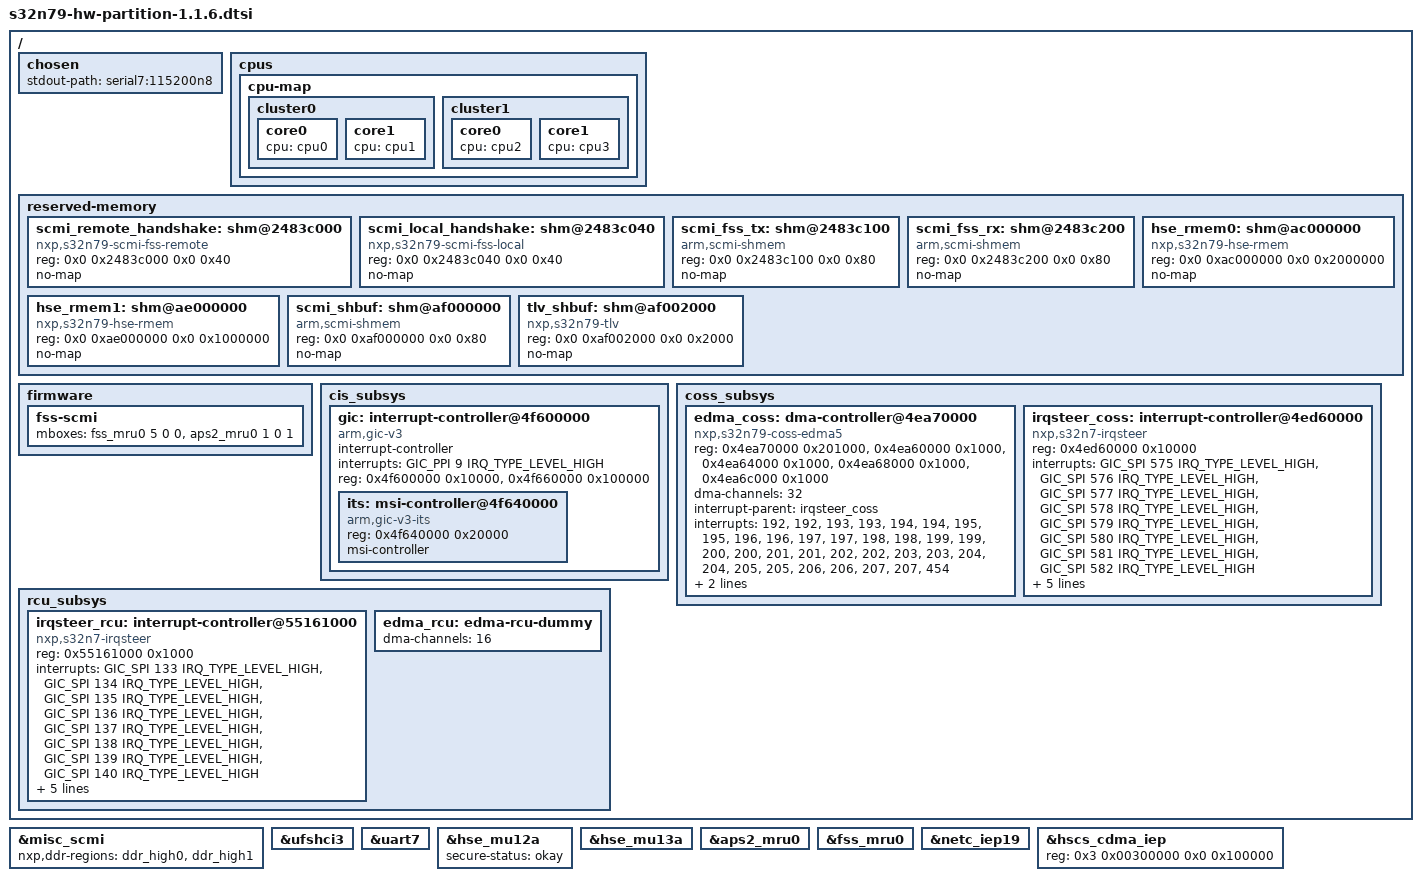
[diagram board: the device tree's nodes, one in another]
// SPDX-License-Identifier: (GPL-2.0+ OR BSD-3-Clause)
/*
 * Copyright 2025-2026 NXP
 */

#include "s32n79-hw-partition-1.1.6-ddr.dtsi"

/delete-node/ &gic;
/delete-node/ &cpu4;
/delete-node/ &cpu5;
/delete-node/ &cpu6;
/delete-node/ &cpu7;
/delete-node/ &irqsteer_coss;
/delete-node/ &irqsteer_rcu;
/delete-node/ &edma_coss;
/delete-node/ &edma_rcu;
/delete-node/ &netc_iep14;
/delete-node/ &netc_iep18;
/delete-node/ &sec_jr0;
/delete-node/ &sec_jr1;
/delete-node/ &sec_jr2;
/delete-node/ &sec_jr3;
/delete-node/ &sec_jr4;
/delete-node/ &sec_jr5;
/delete-node/ &sec_jr6;
/delete-node/ &sec_jr7;
/delete-node/ &sec_jr8;
/delete-node/ &sec_jr9;
/delete-node/ &sec_jr10;
/delete-node/ &sec_jr11;
/delete-node/ &ufshc;
/delete-node/ &ufshci0;
/delete-node/ &ufshci1;
/delete-node/ &ufshci2;

/ {
	chosen {
		stdout-path = "serial7:115200n8";
	};

	cpus {
		cpu-map {
			cluster0 {
				core0 {
					cpu = <&cpu0>;
				};

				core1 {
					cpu = <&cpu1>;
				};
			};

			cluster1 {
				core0 {
					cpu = <&cpu2>;
				};

				core1 {
					cpu = <&cpu3>;
				};
			};
		};
	};

	reserved-memory {
		#address-cells = <2>;
		#size-cells = <2>;
		ranges;

		scmi_remote_handshake: shm@2483c000 {
			compatible = "nxp,s32n79-scmi-fss-remote";
			reg = <0x0 0x2483c000 0x0 0x40>;
			no-map;
		};

		scmi_local_handshake: shm@2483c040 {
			compatible = "nxp,s32n79-scmi-fss-local";
			reg = <0x0 0x2483c040 0x0 0x40>;
			no-map;
		};
		/* FSS SCMI TX Mailbox */
		scmi_fss_tx: shm@2483c100 {
			compatible = "arm,scmi-shmem";
			reg = <0x0 0x2483c100 0x0 0x80>;
			no-map;
		};

		/* FSS SCMI RX Mailbox */
		scmi_fss_rx: shm@2483c200 {
			compatible = "arm,scmi-shmem";
			reg = <0x0 0x2483c200 0x0 0x80>;
			no-map;
		};

		hse_rmem0: shm@ac000000 {
			compatible = "nxp,s32n79-hse-rmem";
			reg = <0x0 0xac000000 0x0 0x2000000>; /* 32 MB */
			no-map;
		};

		hse_rmem1: shm@ae000000 {
			compatible = "nxp,s32n79-hse-rmem";
			reg = <0x0 0xae000000 0x0 0x1000000>; /* 16 MB */
			no-map;
		};

		scmi_shbuf: shm@af000000 {
			compatible = "arm,scmi-shmem";
			reg = <0x0 0xaf000000 0x0 0x80>;
			no-map;
		};

		tlv_shbuf: shm@af002000 {
			compatible = "nxp,s32n79-tlv";
			reg = <0x0 0xaf002000 0x0 0x2000>;
			no-map;
		};
	};

	firmware {
		fss-scmi {
			/*
			 * mru instance, chan, mailbox, tx/rx
			 * type: SCMI_TX -> 0
			 * type: SCMI_RX -> 1
			 */
			mboxes = <&fss_mru0 5 0 0>, <&aps2_mru0 1 0 1>;
		};
	};

	cis_subsys {
		gic: interrupt-controller@4f600000 {
			compatible = "arm,gic-v3";
			#address-cells = <1>;
			#size-cells = <1>;
			#interrupt-cells = <3>;
			interrupt-controller;
			interrupts = <GIC_PPI 9 IRQ_TYPE_LEVEL_HIGH>;
			reg = <0x4f600000 0x10000>, /* GIC Dist */
			      <0x4f660000 0x100000>; /* GICR (RD_base + SGI_base) */
			ranges;

			its: msi-controller@4f640000 {
				compatible = "arm,gic-v3-its";
				reg = <0x4f640000 0x20000>;
				msi-controller;
			};
		};

	};

	coss_subsys {
		edma_coss: dma-controller@4ea70000 {
			compatible = "nxp,s32n79-coss-edma5";
			reg = <0x4ea70000 0x201000>,
			      <0x4ea60000 0x1000>,
			      <0x4ea64000 0x1000>,
			      <0x4ea68000 0x1000>,
			      <0x4ea6c000 0x1000>;
			#dma-cells = <2>;
			dma-channels = <32>;
			interrupt-parent = <&irqsteer_coss>;
			/* Two DMA channels share the same interrupt. */
			interrupts = <192>, <192>, <193>, <193>,
				     <194>, <194>, <195>, <195>,
				     <196>, <196>, <197>, <197>,
				     <198>, <198>, <199>, <199>,
				     <200>, <200>, <201>, <201>,
				     <202>, <202>, <203>, <203>,
				     <204>, <204>, <205>, <205>,
				     <206>, <206>, <207>, <207>,
				     <454>;
			clocks = <&clks 0x90>, <&clks 0x9a>,
				<&clks 0x90>, <&clks 0x9a>;
			clock-names = "dmamux0", "dmamux1", "dmamux2", "dmamux3";
		};

		irqsteer_coss: interrupt-controller@4ed60000 {
			compatible = "nxp,s32n7-irqsteer";
			reg = <0x4ed60000 0x10000>;
			interrupts = <GIC_SPI 575 IRQ_TYPE_LEVEL_HIGH>,
				     <GIC_SPI 576 IRQ_TYPE_LEVEL_HIGH>,
				     <GIC_SPI 577 IRQ_TYPE_LEVEL_HIGH>,
				     <GIC_SPI 578 IRQ_TYPE_LEVEL_HIGH>,
				     <GIC_SPI 579 IRQ_TYPE_LEVEL_HIGH>,
				     <GIC_SPI 580 IRQ_TYPE_LEVEL_HIGH>,
				     <GIC_SPI 581 IRQ_TYPE_LEVEL_HIGH>,
				     <GIC_SPI 582 IRQ_TYPE_LEVEL_HIGH>;
			interrupt-controller;
			interrupt-parent = <&gic>;
			#interrupt-cells = <1>;
			clocks = <&clks 0x9a>;
			clock-names = "ipg";
			fsl,channel = <0>;
			fsl,num-irqs = <512>;
		};
	};

	rcu_subsys {
		irqsteer_rcu: interrupt-controller@55161000 {
			compatible = "nxp,s32n7-irqsteer";
			reg = <0x55161000 0x1000>;
			interrupts = <GIC_SPI 133 IRQ_TYPE_LEVEL_HIGH>,
				     <GIC_SPI 134 IRQ_TYPE_LEVEL_HIGH>,
				     <GIC_SPI 135 IRQ_TYPE_LEVEL_HIGH>,
				     <GIC_SPI 136 IRQ_TYPE_LEVEL_HIGH>,
				     <GIC_SPI 137 IRQ_TYPE_LEVEL_HIGH>,
				     <GIC_SPI 138 IRQ_TYPE_LEVEL_HIGH>,
				     <GIC_SPI 139 IRQ_TYPE_LEVEL_HIGH>,
				     <GIC_SPI 140 IRQ_TYPE_LEVEL_HIGH>;
			interrupt-controller;
			interrupt-parent = <&gic>;
			#interrupt-cells = <1>;
			clocks = <&clks 0xf9>;
			clock-names = "ipg";
			fsl,channel = <0>;
			fsl,num-irqs = <512>;
		};

		edma_rcu: edma-rcu-dummy {
			#dma-cells = <2>;
			dma-channels = <16>;
		};
	};
};

&misc_scmi {
	nxp,ddr-regions = <&ddr_high0>, <&ddr_high1>;
};

&ufshci3 {
	status = "okay";
};

&uart7 {
	status = "okay";
};

&hse_mu12a {
	secure-status = "okay";
};

&hse_mu13a {
	status = "okay";
};

&aps2_mru0 {
	status = "okay";
};

&fss_mru0 {
	status = "okay";
};

&netc_iep19 {
	status = "okay";
};

&hscs_cdma_iep {
	reg = <0x3 0x00300000 0x0 0x100000>;
	status = "okay";
};
